# ipro6s register map
Vendor: intelpro; Series: IPRO6S
CPU: ipro6s, little endian
Registers are 32-bit, read-write, reset 0x0 unless marked. A register's access mark holds for its fields unless they carry their own. Offsets are from the block's base; [hi:lo] are bit positions; {n}, {i} and the like mark numbered series.

## BZ_PHY_AGC
Base 0x30004000
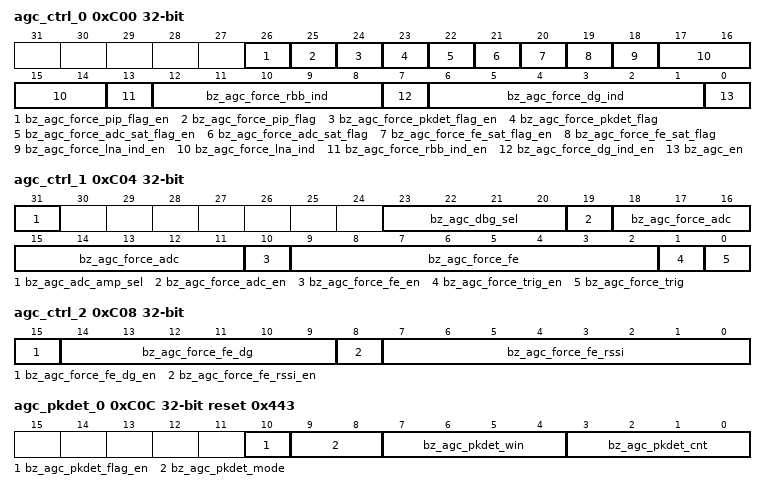
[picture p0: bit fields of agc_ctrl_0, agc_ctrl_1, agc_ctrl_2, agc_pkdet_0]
0xC00 agc_ctrl_0
  [26] bz_agc_force_pip_flag_en, [25] bz_agc_force_pip_flag, [24] bz_agc_force_pkdet_flag_en, [23] bz_agc_force_pkdet_flag, [22] bz_agc_force_adc_sat_flag_en, [21] bz_agc_force_adc_sat_flag, [20] bz_agc_force_fe_sat_flag_en, [19] bz_agc_force_fe_sat_flag, [18] bz_agc_force_lna_ind_en, [17:14] bz_agc_force_lna_ind, [13] bz_agc_force_rbb_ind_en, [12:8] bz_agc_force_rbb_ind, [7] bz_agc_force_dg_ind_en, [6:1] bz_agc_force_dg_ind, [0] bz_agc_en
0xC04 agc_ctrl_1
  [31] bz_agc_adc_amp_sel, [23:20] bz_agc_dbg_sel, [19] bz_agc_force_adc_en, [18:11] bz_agc_force_adc, [10] bz_agc_force_fe_en, [9:2] bz_agc_force_fe, [1] bz_agc_force_trig_en, [0] bz_agc_force_trig
0xC08 agc_ctrl_2
  [15] bz_agc_force_fe_dg_en, [14:9] bz_agc_force_fe_dg, [8] bz_agc_force_fe_rssi_en, [7:0] bz_agc_force_fe_rssi
0xC0C agc_pkdet_0 reset 0x443
  [10] bz_agc_pkdet_flag_en, [9:8] bz_agc_pkdet_mode, [7:4] bz_agc_pkdet_win, [3:0] bz_agc_pkdet_cnt
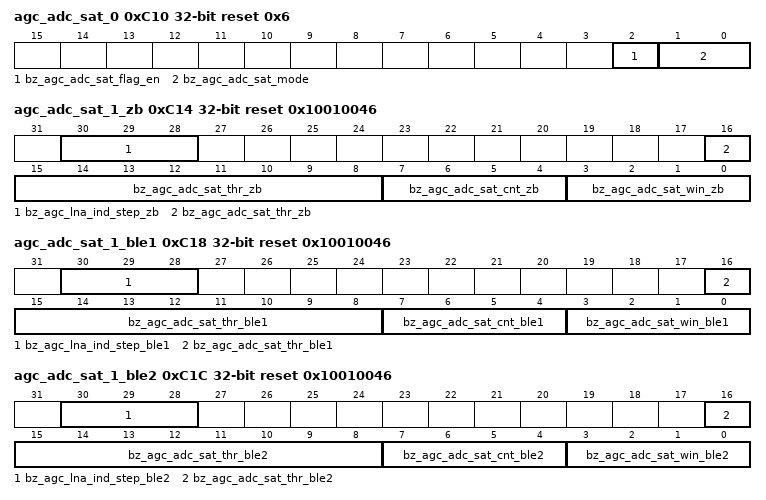
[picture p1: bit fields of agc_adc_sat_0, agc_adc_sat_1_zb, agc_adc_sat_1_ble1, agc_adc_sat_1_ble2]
0xC10 agc_adc_sat_0 reset 0x6
  [2] bz_agc_adc_sat_flag_en, [1:0] bz_agc_adc_sat_mode
0xC14 agc_adc_sat_1_zb reset 0x10010046
  [30:28] bz_agc_lna_ind_step_zb, [16:8] bz_agc_adc_sat_thr_zb, [7:4] bz_agc_adc_sat_cnt_zb, [3:0] bz_agc_adc_sat_win_zb
0xC18 agc_adc_sat_1_ble1 reset 0x10010046
  [30:28] bz_agc_lna_ind_step_ble1, [16:8] bz_agc_adc_sat_thr_ble1, [7:4] bz_agc_adc_sat_cnt_ble1, [3:0] bz_agc_adc_sat_win_ble1
0xC1C agc_adc_sat_1_ble2 reset 0x10010046
  [30:28] bz_agc_lna_ind_step_ble2, [16:8] bz_agc_adc_sat_thr_ble2, [7:4] bz_agc_adc_sat_cnt_ble2, [3:0] bz_agc_adc_sat_win_ble2
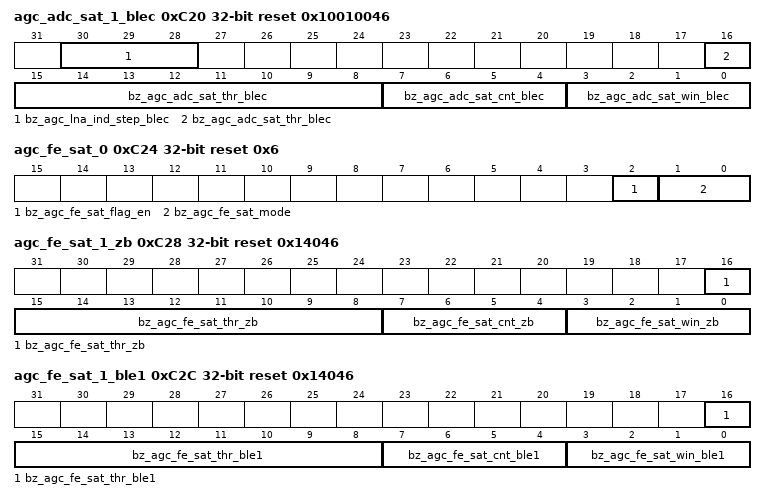
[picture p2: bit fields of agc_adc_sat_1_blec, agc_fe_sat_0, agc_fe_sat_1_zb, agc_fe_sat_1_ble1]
0xC20 agc_adc_sat_1_blec reset 0x10010046
  [30:28] bz_agc_lna_ind_step_blec, [16:8] bz_agc_adc_sat_thr_blec, [7:4] bz_agc_adc_sat_cnt_blec, [3:0] bz_agc_adc_sat_win_blec
0xC24 agc_fe_sat_0 reset 0x6
  [2] bz_agc_fe_sat_flag_en, [1:0] bz_agc_fe_sat_mode
0xC28 agc_fe_sat_1_zb reset 0x14046
  [16:8] bz_agc_fe_sat_thr_zb, [7:4] bz_agc_fe_sat_cnt_zb, [3:0] bz_agc_fe_sat_win_zb
0xC2C agc_fe_sat_1_ble1 reset 0x14046
  [16:8] bz_agc_fe_sat_thr_ble1, [7:4] bz_agc_fe_sat_cnt_ble1, [3:0] bz_agc_fe_sat_win_ble1
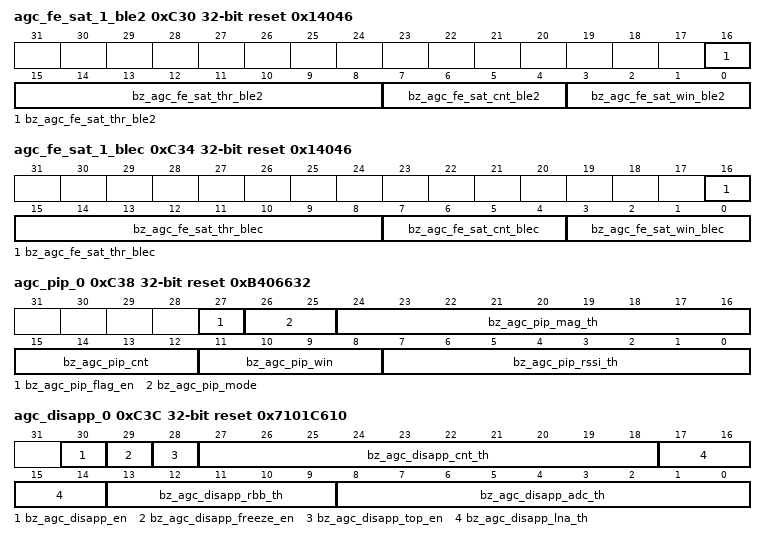
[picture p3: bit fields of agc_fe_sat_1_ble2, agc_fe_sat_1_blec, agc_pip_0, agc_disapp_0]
0xC30 agc_fe_sat_1_ble2 reset 0x14046
  [16:8] bz_agc_fe_sat_thr_ble2, [7:4] bz_agc_fe_sat_cnt_ble2, [3:0] bz_agc_fe_sat_win_ble2
0xC34 agc_fe_sat_1_blec reset 0x14046
  [16:8] bz_agc_fe_sat_thr_blec, [7:4] bz_agc_fe_sat_cnt_blec, [3:0] bz_agc_fe_sat_win_blec
0xC38 agc_pip_0 reset 0xB406632
  [27] bz_agc_pip_flag_en, [26:25] bz_agc_pip_mode, [24:16] bz_agc_pip_mag_th, [15:12] bz_agc_pip_cnt, [11:8] bz_agc_pip_win, [7:0] bz_agc_pip_rssi_th
0xC3C agc_disapp_0 reset 0x7101C610
  [30] bz_agc_disapp_en, [29] bz_agc_disapp_freeze_en, [28] bz_agc_disapp_top_en, [27:18] bz_agc_disapp_cnt_th, [17:14] bz_agc_disapp_lna_th, [13:9] bz_agc_disapp_rbb_th, [8:0] bz_agc_disapp_adc_th
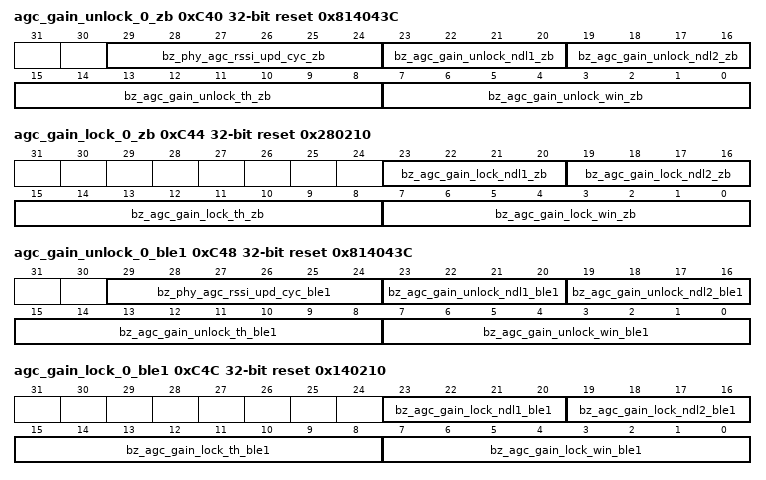
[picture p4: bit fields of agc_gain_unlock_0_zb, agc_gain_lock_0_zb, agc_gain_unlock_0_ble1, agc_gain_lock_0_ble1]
0xC40 agc_gain_unlock_0_zb reset 0x814043C
  [29:24] bz_phy_agc_rssi_upd_cyc_zb, [23:20] bz_agc_gain_unlock_ndl1_zb, [19:16] bz_agc_gain_unlock_ndl2_zb, [15:8] bz_agc_gain_unlock_th_zb, [7:0] bz_agc_gain_unlock_win_zb
0xC44 agc_gain_lock_0_zb reset 0x280210
  [23:20] bz_agc_gain_lock_ndl1_zb, [19:16] bz_agc_gain_lock_ndl2_zb, [15:8] bz_agc_gain_lock_th_zb, [7:0] bz_agc_gain_lock_win_zb
0xC48 agc_gain_unlock_0_ble1 reset 0x814043C
  [29:24] bz_phy_agc_rssi_upd_cyc_ble1, [23:20] bz_agc_gain_unlock_ndl1_ble1, [19:16] bz_agc_gain_unlock_ndl2_ble1, [15:8] bz_agc_gain_unlock_th_ble1, [7:0] bz_agc_gain_unlock_win_ble1
0xC4C agc_gain_lock_0_ble1 reset 0x140210
  [23:20] bz_agc_gain_lock_ndl1_ble1, [19:16] bz_agc_gain_lock_ndl2_ble1, [15:8] bz_agc_gain_lock_th_ble1, [7:0] bz_agc_gain_lock_win_ble1
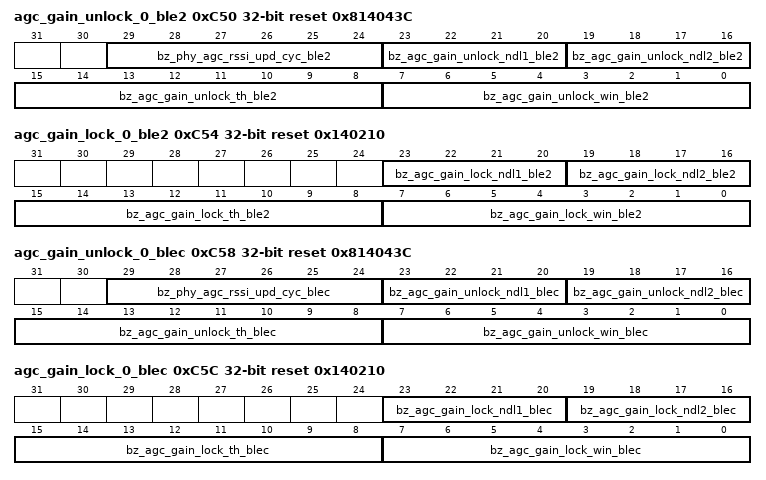
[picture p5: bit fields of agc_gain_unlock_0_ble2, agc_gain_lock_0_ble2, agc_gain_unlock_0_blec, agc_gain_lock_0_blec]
0xC50 agc_gain_unlock_0_ble2 reset 0x814043C
  [29:24] bz_phy_agc_rssi_upd_cyc_ble2, [23:20] bz_agc_gain_unlock_ndl1_ble2, [19:16] bz_agc_gain_unlock_ndl2_ble2, [15:8] bz_agc_gain_unlock_th_ble2, [7:0] bz_agc_gain_unlock_win_ble2
0xC54 agc_gain_lock_0_ble2 reset 0x140210
  [23:20] bz_agc_gain_lock_ndl1_ble2, [19:16] bz_agc_gain_lock_ndl2_ble2, [15:8] bz_agc_gain_lock_th_ble2, [7:0] bz_agc_gain_lock_win_ble2
0xC58 agc_gain_unlock_0_blec reset 0x814043C
  [29:24] bz_phy_agc_rssi_upd_cyc_blec, [23:20] bz_agc_gain_unlock_ndl1_blec, [19:16] bz_agc_gain_unlock_ndl2_blec, [15:8] bz_agc_gain_unlock_th_blec, [7:0] bz_agc_gain_unlock_win_blec
0xC5C agc_gain_lock_0_blec reset 0x140210
  [23:20] bz_agc_gain_lock_ndl1_blec, [19:16] bz_agc_gain_lock_ndl2_blec, [15:8] bz_agc_gain_lock_th_blec, [7:0] bz_agc_gain_lock_win_blec
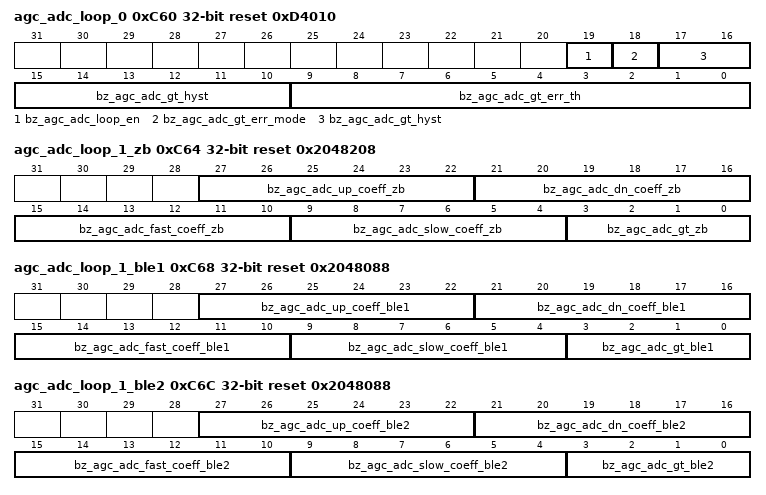
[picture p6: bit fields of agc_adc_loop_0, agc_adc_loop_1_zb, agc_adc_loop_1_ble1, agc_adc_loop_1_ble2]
0xC60 agc_adc_loop_0 reset 0xD4010
  [19] bz_agc_adc_loop_en, [18] bz_agc_adc_gt_err_mode, [17:10] bz_agc_adc_gt_hyst, [9:0] bz_agc_adc_gt_err_th
0xC64 agc_adc_loop_1_zb reset 0x2048208
  [27:22] bz_agc_adc_up_coeff_zb, [21:16] bz_agc_adc_dn_coeff_zb, [15:10] bz_agc_adc_fast_coeff_zb, [9:4] bz_agc_adc_slow_coeff_zb, [3:0] bz_agc_adc_gt_zb
0xC68 agc_adc_loop_1_ble1 reset 0x2048088
  [27:22] bz_agc_adc_up_coeff_ble1, [21:16] bz_agc_adc_dn_coeff_ble1, [15:10] bz_agc_adc_fast_coeff_ble1, [9:4] bz_agc_adc_slow_coeff_ble1, [3:0] bz_agc_adc_gt_ble1
0xC6C agc_adc_loop_1_ble2 reset 0x2048088
  [27:22] bz_agc_adc_up_coeff_ble2, [21:16] bz_agc_adc_dn_coeff_ble2, [15:10] bz_agc_adc_fast_coeff_ble2, [9:4] bz_agc_adc_slow_coeff_ble2, [3:0] bz_agc_adc_gt_ble2
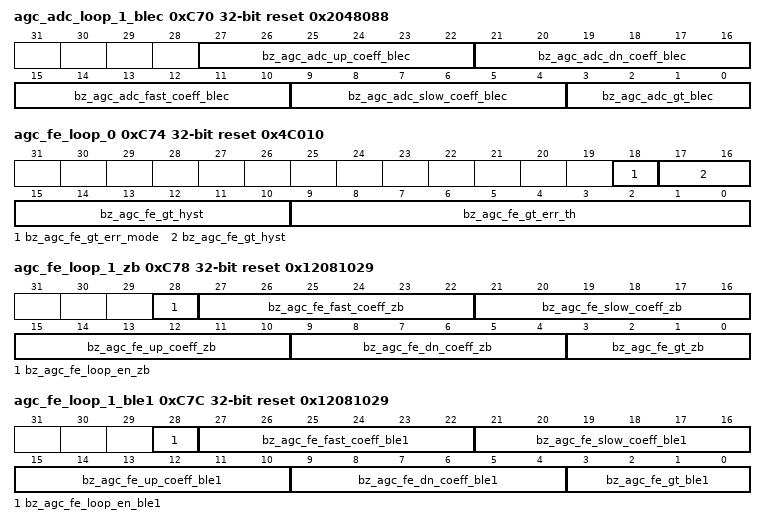
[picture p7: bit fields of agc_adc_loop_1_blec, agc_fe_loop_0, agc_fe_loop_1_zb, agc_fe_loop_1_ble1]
0xC70 agc_adc_loop_1_blec reset 0x2048088
  [27:22] bz_agc_adc_up_coeff_blec, [21:16] bz_agc_adc_dn_coeff_blec, [15:10] bz_agc_adc_fast_coeff_blec, [9:4] bz_agc_adc_slow_coeff_blec, [3:0] bz_agc_adc_gt_blec
0xC74 agc_fe_loop_0 reset 0x4C010
  [18] bz_agc_fe_gt_err_mode, [17:10] bz_agc_fe_gt_hyst, [9:0] bz_agc_fe_gt_err_th
0xC78 agc_fe_loop_1_zb reset 0x12081029
  [28] bz_agc_fe_loop_en_zb, [27:22] bz_agc_fe_fast_coeff_zb, [21:16] bz_agc_fe_slow_coeff_zb, [15:10] bz_agc_fe_up_coeff_zb, [9:4] bz_agc_fe_dn_coeff_zb, [3:0] bz_agc_fe_gt_zb
0xC7C agc_fe_loop_1_ble1 reset 0x12081029
  [28] bz_agc_fe_loop_en_ble1, [27:22] bz_agc_fe_fast_coeff_ble1, [21:16] bz_agc_fe_slow_coeff_ble1, [15:10] bz_agc_fe_up_coeff_ble1, [9:4] bz_agc_fe_dn_coeff_ble1, [3:0] bz_agc_fe_gt_ble1
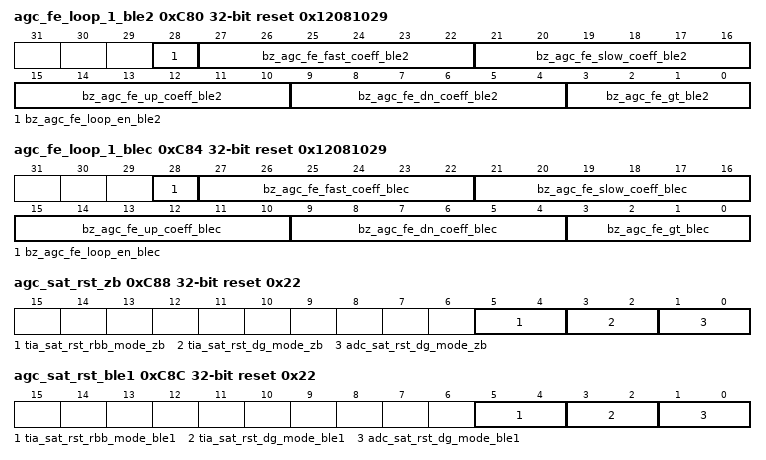
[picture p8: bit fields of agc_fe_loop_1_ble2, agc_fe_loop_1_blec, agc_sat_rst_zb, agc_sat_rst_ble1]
0xC80 agc_fe_loop_1_ble2 reset 0x12081029
  [28] bz_agc_fe_loop_en_ble2, [27:22] bz_agc_fe_fast_coeff_ble2, [21:16] bz_agc_fe_slow_coeff_ble2, [15:10] bz_agc_fe_up_coeff_ble2, [9:4] bz_agc_fe_dn_coeff_ble2, [3:0] bz_agc_fe_gt_ble2
0xC84 agc_fe_loop_1_blec reset 0x12081029
  [28] bz_agc_fe_loop_en_blec, [27:22] bz_agc_fe_fast_coeff_blec, [21:16] bz_agc_fe_slow_coeff_blec, [15:10] bz_agc_fe_up_coeff_blec, [9:4] bz_agc_fe_dn_coeff_blec, [3:0] bz_agc_fe_gt_blec
0xC88 agc_sat_rst_zb reset 0x22
  [5:4] tia_sat_rst_rbb_mode_zb, [3:2] tia_sat_rst_dg_mode_zb, [1:0] adc_sat_rst_dg_mode_zb
0xC8C agc_sat_rst_ble1 reset 0x22
  [5:4] tia_sat_rst_rbb_mode_ble1, [3:2] tia_sat_rst_dg_mode_ble1, [1:0] adc_sat_rst_dg_mode_ble1
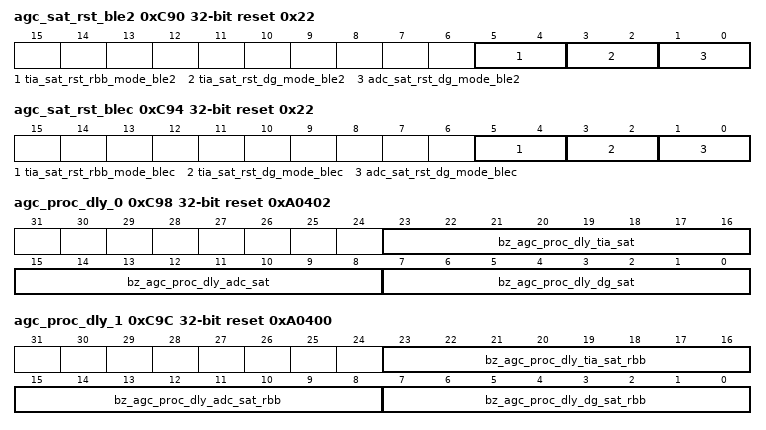
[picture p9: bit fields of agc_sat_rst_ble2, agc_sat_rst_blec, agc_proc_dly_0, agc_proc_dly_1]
0xC90 agc_sat_rst_ble2 reset 0x22
  [5:4] tia_sat_rst_rbb_mode_ble2, [3:2] tia_sat_rst_dg_mode_ble2, [1:0] adc_sat_rst_dg_mode_ble2
0xC94 agc_sat_rst_blec reset 0x22
  [5:4] tia_sat_rst_rbb_mode_blec, [3:2] tia_sat_rst_dg_mode_blec, [1:0] adc_sat_rst_dg_mode_blec
0xC98 agc_proc_dly_0 reset 0xA0402
  [23:16] bz_agc_proc_dly_tia_sat, [15:8] bz_agc_proc_dly_adc_sat, [7:0] bz_agc_proc_dly_dg_sat
0xC9C agc_proc_dly_1 reset 0xA0400
  [23:16] bz_agc_proc_dly_tia_sat_rbb, [15:8] bz_agc_proc_dly_adc_sat_rbb, [7:0] bz_agc_proc_dly_dg_sat_rbb
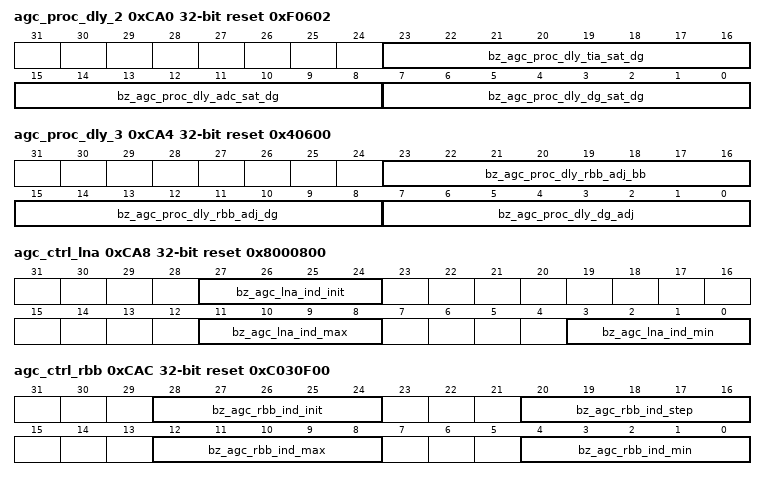
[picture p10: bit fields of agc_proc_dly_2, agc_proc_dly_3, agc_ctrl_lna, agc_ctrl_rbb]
0xCA0 agc_proc_dly_2 reset 0xF0602
  [23:16] bz_agc_proc_dly_tia_sat_dg, [15:8] bz_agc_proc_dly_adc_sat_dg, [7:0] bz_agc_proc_dly_dg_sat_dg
0xCA4 agc_proc_dly_3 reset 0x40600
  [23:16] bz_agc_proc_dly_rbb_adj_bb, [15:8] bz_agc_proc_dly_rbb_adj_dg, [7:0] bz_agc_proc_dly_dg_adj
0xCA8 agc_ctrl_lna reset 0x8000800
  [27:24] bz_agc_lna_ind_init, [11:8] bz_agc_lna_ind_max, [3:0] bz_agc_lna_ind_min
0xCAC agc_ctrl_rbb reset 0xC030F00
  [28:24] bz_agc_rbb_ind_init, [20:16] bz_agc_rbb_ind_step, [12:8] bz_agc_rbb_ind_max, [4:0] bz_agc_rbb_ind_min
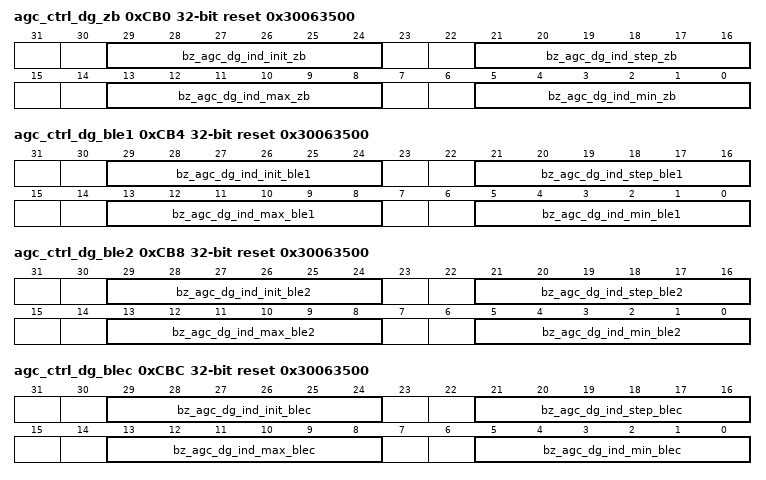
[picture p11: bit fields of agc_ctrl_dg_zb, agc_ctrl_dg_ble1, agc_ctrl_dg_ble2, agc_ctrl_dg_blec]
0xCB0 agc_ctrl_dg_zb reset 0x30063500
  [29:24] bz_agc_dg_ind_init_zb, [21:16] bz_agc_dg_ind_step_zb, [13:8] bz_agc_dg_ind_max_zb, [5:0] bz_agc_dg_ind_min_zb
0xCB4 agc_ctrl_dg_ble1 reset 0x30063500
  [29:24] bz_agc_dg_ind_init_ble1, [21:16] bz_agc_dg_ind_step_ble1, [13:8] bz_agc_dg_ind_max_ble1, [5:0] bz_agc_dg_ind_min_ble1
0xCB8 agc_ctrl_dg_ble2 reset 0x30063500
  [29:24] bz_agc_dg_ind_init_ble2, [21:16] bz_agc_dg_ind_step_ble2, [13:8] bz_agc_dg_ind_max_ble2, [5:0] bz_agc_dg_ind_min_ble2
0xCBC agc_ctrl_dg_blec reset 0x30063500
  [29:24] bz_agc_dg_ind_init_blec, [21:16] bz_agc_dg_ind_step_blec, [13:8] bz_agc_dg_ind_max_blec, [5:0] bz_agc_dg_ind_min_blec
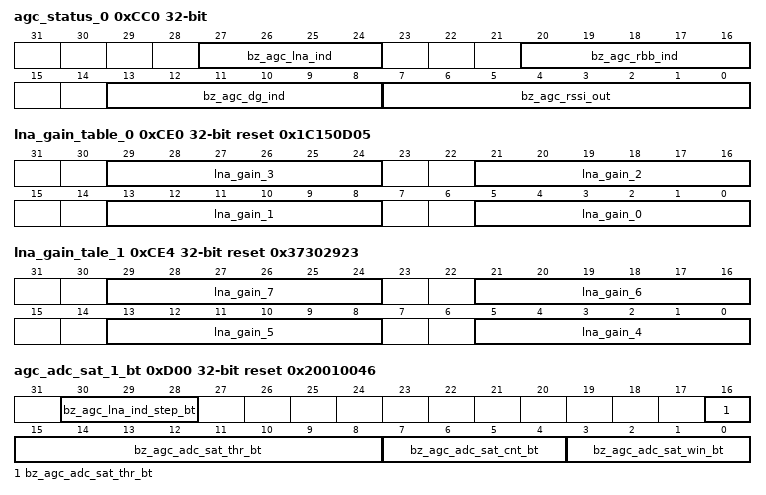
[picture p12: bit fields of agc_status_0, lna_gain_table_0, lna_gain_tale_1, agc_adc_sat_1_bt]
0xCC0 agc_status_0 reset not defined
  [27:24] bz_agc_lna_ind ro, [20:16] bz_agc_rbb_ind ro, [13:8] bz_agc_dg_ind ro, [7:0] bz_agc_rssi_out ro
{0xCC0+4i} agc_status_{i} reset not defined (i=1..3)
  [31:0] bz_agc_status_{i} ro
0xCD0 agc_ctrl_reserved reset 0xFFFF
0xCDC agc_ctrl_misc
  [0] cfg_dg_adj_minus_1_ctrl_rollback
0xCE0 lna_gain_table_0 reset 0x1C150D05
  [8n+5:8n] lna_gain_{n} (n=0..3)
0xCE4 lna_gain_tale_1 reset 0x37302923
  [8n-27:8n-32] lna_gain_{n} (n=4..7)
0xCE8 lna_gain_tale_2 reset 0x3D
  [5:0] lna_gain_8
0xD00 agc_adc_sat_1_bt reset 0x20010046
  [30:28] bz_agc_lna_ind_step_bt, [16:8] bz_agc_adc_sat_thr_bt, [7:4] bz_agc_adc_sat_cnt_bt, [3:0] bz_agc_adc_sat_win_bt
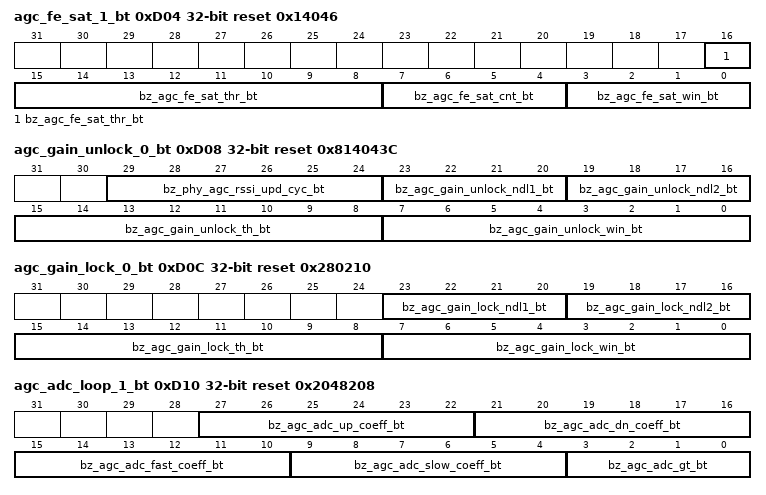
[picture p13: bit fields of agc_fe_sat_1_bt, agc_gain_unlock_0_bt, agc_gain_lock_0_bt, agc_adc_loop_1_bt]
0xD04 agc_fe_sat_1_bt reset 0x14046
  [16:8] bz_agc_fe_sat_thr_bt, [7:4] bz_agc_fe_sat_cnt_bt, [3:0] bz_agc_fe_sat_win_bt
0xD08 agc_gain_unlock_0_bt reset 0x814043C
  [29:24] bz_phy_agc_rssi_upd_cyc_bt, [23:20] bz_agc_gain_unlock_ndl1_bt, [19:16] bz_agc_gain_unlock_ndl2_bt, [15:8] bz_agc_gain_unlock_th_bt, [7:0] bz_agc_gain_unlock_win_bt
0xD0C agc_gain_lock_0_bt reset 0x280210
  [23:20] bz_agc_gain_lock_ndl1_bt, [19:16] bz_agc_gain_lock_ndl2_bt, [15:8] bz_agc_gain_lock_th_bt, [7:0] bz_agc_gain_lock_win_bt
0xD10 agc_adc_loop_1_bt reset 0x2048208
  [27:22] bz_agc_adc_up_coeff_bt, [21:16] bz_agc_adc_dn_coeff_bt, [15:10] bz_agc_adc_fast_coeff_bt, [9:4] bz_agc_adc_slow_coeff_bt, [3:0] bz_agc_adc_gt_bt
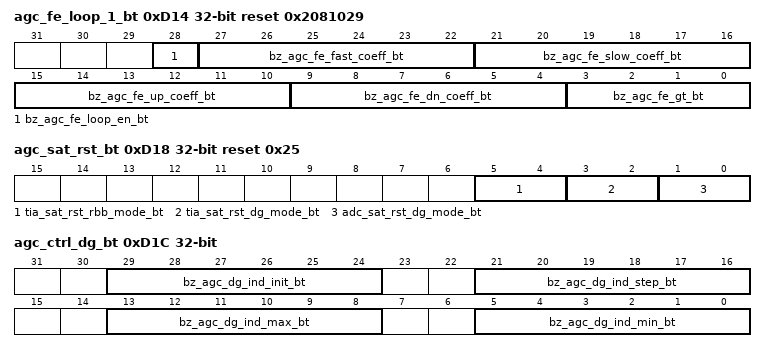
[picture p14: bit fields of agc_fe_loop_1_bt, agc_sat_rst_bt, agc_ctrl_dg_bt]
0xD14 agc_fe_loop_1_bt reset 0x2081029
  [28] bz_agc_fe_loop_en_bt, [27:22] bz_agc_fe_fast_coeff_bt, [21:16] bz_agc_fe_slow_coeff_bt, [15:10] bz_agc_fe_up_coeff_bt, [9:4] bz_agc_fe_dn_coeff_bt, [3:0] bz_agc_fe_gt_bt
0xD18 agc_sat_rst_bt reset 0x25
  [5:4] tia_sat_rst_rbb_mode_bt
  [3:2] tia_sat_rst_dg_mode_bt — force dg = 0 for BT mode
  [1:0] adc_sat_rst_dg_mode_bt — force dg = 0 for BT mode
0xD1C agc_ctrl_dg_bt
  [29:24] bz_agc_dg_ind_init_bt — force dg = 0 for BT mode
  [21:16] bz_agc_dg_ind_step_bt — force dg = 0 for BT mode
  [13:8] bz_agc_dg_ind_max_bt — force dg = 0 for BT mode
  [5:0] bz_agc_dg_ind_min_bt — force dg = 0 for BT mode
